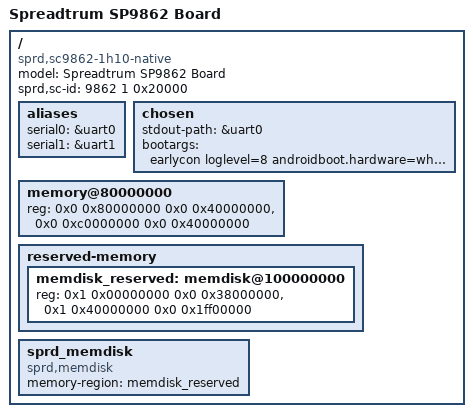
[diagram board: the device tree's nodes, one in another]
/*
 * Spreadtrum SP9862_1 board DTS file
 *
 * Copyright (C) 2016, Spreadtrum Communications Inc.
 *
 * This file is licensed under a dual GPLv2 or X11 license.
 */

/dts-v1/;

#include "sc9862.dtsi"
#include "sp9862-common.dtsi"

/ {
	model = "Spreadtrum SP9862 Board";
	compatible = "sprd,sc9862-1h10-native";
	sprd,sc-id = <9862 1 0x20000>;
	#address-cells = <2>;
	#size-cells = <2>;

	aliases {
		serial0 = &uart0;
		serial1 = &uart1;
	};


	chosen {
		stdout-path = &uart0;
		bootargs = "earlycon loglevel=8 androidboot.hardware=whalek androidboot.selinux=permissive";
	};

	memory@80000000 {
		device_type = "memory";
		reg = <0x0 0x80000000 0x0 0x40000000>,
		      <0x0 0xc0000000 0x0 0x40000000>;
	};

	reserved-memory {
		#address-cells = <2>;
		#size-cells = <2>;
		ranges;
		memdisk_reserved: memdisk@100000000{
			reg = <0x1 0x00000000 0x0 0x38000000>,   /* system */
				<0x1 0x40000000 0x0 0x1ff00000>; /* userdata */
		};
	};

	sprd_memdisk {
		compatible = "sprd,memdisk";
		memory-region = <&memdisk_reserved>;
	};
};








